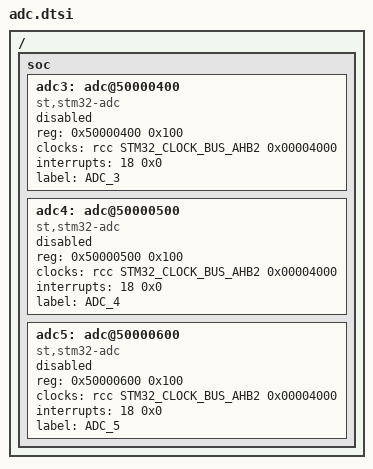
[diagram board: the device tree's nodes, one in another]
/*
 * Copyright (c) 2022 OwnTech.
 *
 * SPDX-License-Identifier: LGLPV2.1
 *
 * Ideally, this file's content should be contributed
 * to Zephyr's definition of STM32G4 SOC.
 */

 / {
	soc {
		adc3: adc@50000400 {
			compatible = "st,stm32-adc";
			reg = < 0x50000400 0x100 >;
			clocks = < &rcc STM32_CLOCK_BUS_AHB2 0x00004000 >;
			interrupts = < 18 0x0 >;
			status = "disabled";
			label = "ADC_3";
			#io-channel-cells = < 0x1 >;
		};

		adc4: adc@50000500 {
			compatible = "st,stm32-adc";
			reg = < 0x50000500 0x100 >;
			clocks = < &rcc STM32_CLOCK_BUS_AHB2 0x00004000 >;
			interrupts = < 18 0x0 >;
			status = "disabled";
			label = "ADC_4";
			#io-channel-cells = < 0x1 >;
		};

		adc5: adc@50000600 {
			compatible = "st,stm32-adc";
			reg = < 0x50000600 0x100 >;
			clocks = < &rcc STM32_CLOCK_BUS_AHB2 0x00004000 >;
			interrupts = < 18 0x0 >;
			status = "disabled";
			label = "ADC_5";
			#io-channel-cells = < 0x1 >;
		};
	};
};
